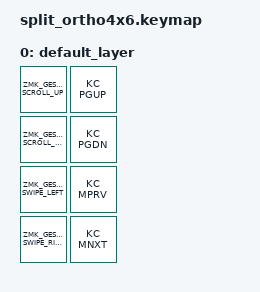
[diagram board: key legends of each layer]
#include <behaviors.dtsi>
#include <dt-bindings/zmk/keys.h>

#include "../../../config/keymap.keymap"

/ {
    keymap {
        compatible = "zmk,keymap";

        /* 既存のレイヤー構造を維持しつつ、ジェスチャーのバインドを追加 */
        default_layer {
            bindings = <
                /* ... 既存のキーバインド ... */

                /* 2本指スクロールとスワイプのバインド例 */
                ZMK_GESTURE_SCROLL_UP       KC_PGUP
                ZMK_GESTURE_SCROLL_DOWN     KC_PGDN
                
                ZMK_GESTURE_SWIPE_LEFT      &kp KC_MPRV
                ZMK_GESTURE_SWIPE_RIGHT     &kp KC_MNXT

                /* ... 既存のキーバインド ... */
            >;
        };

        /* ... 他のレイヤー定義 ... */
    };
};
